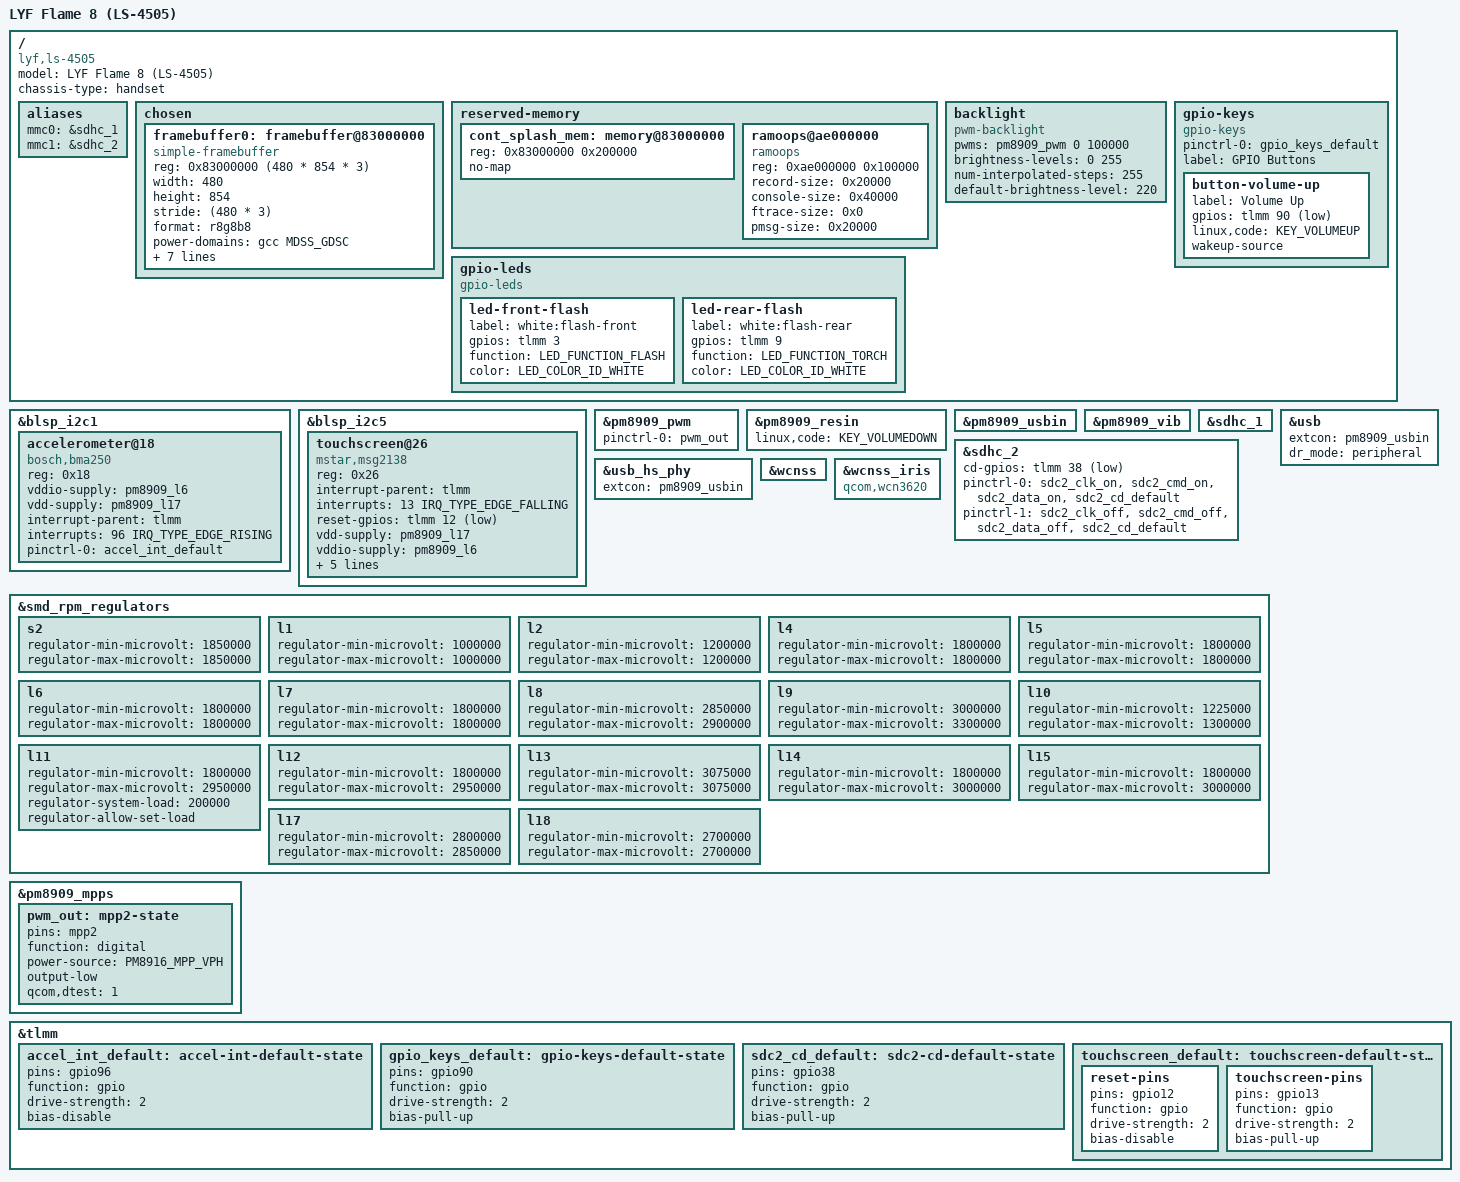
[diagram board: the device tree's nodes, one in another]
// SPDX-License-Identifier: GPL-2.0-only

/dts-v1/;

#include "qcom-msm8909-pm8909.dtsi"

#include <dt-bindings/gpio/gpio.h>
#include <dt-bindings/input/input.h>
#include <dt-bindings/interrupt-controller/irq.h>
#include <dt-bindings/leds/common.h>
#include <dt-bindings/pinctrl/qcom,pmic-mpp.h>

/ {
	model = "LYF Flame 8 (LS-4505)";
	compatible = "lyf,ls-4505", "qcom,msm8909";
	chassis-type = "handset";

	aliases {
		mmc0 = &sdhc_1;
		mmc1 = &sdhc_2;
	};

	chosen {
		#address-cells = <1>;
		#size-cells = <1>;
		ranges;

		framebuffer0: framebuffer@83000000 {
			compatible = "simple-framebuffer";
			reg = <0x83000000 (480 * 854 * 3)>;
			width = <480>;
			height = <854>;
			stride = <(480 * 3)>;
			format = "r8g8b8";

			power-domains = <&gcc MDSS_GDSC>;
			clocks = <&gcc GCC_MDSS_AHB_CLK>,
				 <&gcc GCC_MDSS_AXI_CLK>,
				 <&gcc GCC_MDSS_VSYNC_CLK>,
				 <&gcc GCC_MDSS_MDP_CLK>,
				 <&gcc GCC_MDSS_BYTE0_CLK>,
				 <&gcc GCC_MDSS_PCLK0_CLK>,
				 <&gcc GCC_MDSS_ESC0_CLK>;
		};
	};

	reserved-memory {
		#address-cells = <1>;
		#size-cells = <1>;
		ranges;

		cont_splash_mem: memory@83000000 {
			reg = <0x83000000 0x200000>;
			no-map;
		};

		ramoops@ae000000 {
			compatible = "ramoops";
			reg = <0xae000000 0x100000>;
			record-size = <0x20000>;
			console-size = <0x40000>;
			ftrace-size = <0x0>;
			pmsg-size = <0x20000>;
		};
	};

	backlight: backlight {
		compatible = "pwm-backlight";
		pwms = <&pm8909_pwm 0 100000>;
		brightness-levels = <0 255>;
		num-interpolated-steps = <255>;
		default-brightness-level = <220>;
	};

	gpio-keys {
		compatible = "gpio-keys";
		pinctrl-0 = <&gpio_keys_default>;
		pinctrl-names = "default";
		label = "GPIO Buttons";

		button-volume-up {
			label = "Volume Up";
			gpios = <&tlmm 90 GPIO_ACTIVE_LOW>;
			linux,code = <KEY_VOLUMEUP>;
			wakeup-source;
		};
	};

	gpio-leds {
		compatible = "gpio-leds";

		led-front-flash {
			label = "white:flash-front";
			gpios = <&tlmm 3 GPIO_ACTIVE_HIGH>;
			function = LED_FUNCTION_FLASH;
			color = <LED_COLOR_ID_WHITE>;
		};

		led-rear-flash {
			label = "white:flash-rear";
			gpios = <&tlmm 9 GPIO_ACTIVE_HIGH>;
			function = LED_FUNCTION_TORCH;
			color = <LED_COLOR_ID_WHITE>;
		};
	};
};

&blsp_i2c1 {
	status = "okay";

	accelerometer@18 {
		compatible = "bosch,bma250";
		reg = <0x18>;

		vddio-supply = <&pm8909_l6>;
		vdd-supply = <&pm8909_l17>;

		interrupt-parent = <&tlmm>;
		interrupts = <96 IRQ_TYPE_EDGE_RISING>;

		pinctrl-0 = <&accel_int_default>;
		pinctrl-names = "default";
	};
};

&blsp_i2c5 {
	status = "okay";

	touchscreen@26 {
		compatible = "mstar,msg2138";
		reg = <0x26>;

		interrupt-parent = <&tlmm>;
		interrupts = <13 IRQ_TYPE_EDGE_FALLING>;
		reset-gpios = <&tlmm 12 GPIO_ACTIVE_LOW>;

		vdd-supply = <&pm8909_l17>;
		vddio-supply = <&pm8909_l6>;

		touchscreen-size-x = <2048>;
		touchscreen-size-y = <2048>;

		linux,keycodes = <KEY_APPSELECT KEY_HOMEPAGE KEY_BACK>;

		pinctrl-0 = <&touchscreen_default>;
		pinctrl-names = "default";
	};
};

&pm8909_pwm {
	pinctrl-0 = <&pwm_out>;
	pinctrl-names = "default";
	status = "okay";
};

&pm8909_resin {
	linux,code = <KEY_VOLUMEDOWN>;
	status = "okay";
};

&pm8909_usbin {
	status = "okay";
};

&pm8909_vib {
	status = "okay";
};

&sdhc_1 {
	status = "okay";
};

&sdhc_2 {
	cd-gpios = <&tlmm 38 GPIO_ACTIVE_LOW>;
	pinctrl-0 = <&sdc2_clk_on &sdc2_cmd_on &sdc2_data_on &sdc2_cd_default>;
	pinctrl-1 = <&sdc2_clk_off &sdc2_cmd_off &sdc2_data_off &sdc2_cd_default>;
	pinctrl-names = "default", "sleep";
	status = "okay";
};

&usb {
	extcon = <&pm8909_usbin>;
	dr_mode = "peripheral";
	status = "okay";
};

&usb_hs_phy {
	extcon = <&pm8909_usbin>;
};

&wcnss {
	status = "okay";
};

&wcnss_iris {
	compatible = "qcom,wcn3620";
};

&smd_rpm_regulators {
	s2 {
		regulator-min-microvolt = <1850000>;
		regulator-max-microvolt = <1850000>;
	};
	l1 {
		regulator-min-microvolt = <1000000>;
		regulator-max-microvolt = <1000000>;
	};
	l2 {
		regulator-min-microvolt = <1200000>;
		regulator-max-microvolt = <1200000>;
	};
	l4 {
		regulator-min-microvolt = <1800000>;
		regulator-max-microvolt = <1800000>;
	};
	l5 {
		regulator-min-microvolt = <1800000>;
		regulator-max-microvolt = <1800000>;
	};
	l6 {
		regulator-min-microvolt = <1800000>;
		regulator-max-microvolt = <1800000>;
	};
	l7 {
		regulator-min-microvolt = <1800000>;
		regulator-max-microvolt = <1800000>;
	};
	l8 {
		regulator-min-microvolt = <2850000>;
		regulator-max-microvolt = <2900000>;
	};
	l9 {
		regulator-min-microvolt = <3000000>;
		regulator-max-microvolt = <3300000>;
	};
	l10 {
		regulator-min-microvolt = <1225000>;
		regulator-max-microvolt = <1300000>;
	};
	l11 {
		regulator-min-microvolt = <1800000>;
		regulator-max-microvolt = <2950000>;
		regulator-system-load = <200000>;
		regulator-allow-set-load;
	};
	l12 {
		regulator-min-microvolt = <1800000>;
		regulator-max-microvolt = <2950000>;
	};
	l13 {
		regulator-min-microvolt = <3075000>;
		regulator-max-microvolt = <3075000>;
	};
	l14 {
		regulator-min-microvolt = <1800000>;
		regulator-max-microvolt = <3000000>;
	};
	l15 {
		regulator-min-microvolt = <1800000>;
		regulator-max-microvolt = <3000000>;
	};
	l17 {
		regulator-min-microvolt = <2800000>;
		regulator-max-microvolt = <2850000>;
	};
	l18 {
		regulator-min-microvolt = <2700000>;
		regulator-max-microvolt = <2700000>;
	};
};

&pm8909_mpps {
	pwm_out: mpp2-state {
		pins = "mpp2";
		function = "digital";
		power-source = <PM8916_MPP_VPH>;
		output-low;
		qcom,dtest = <1>;
	};
};

&tlmm {
	accel_int_default: accel-int-default-state {
		pins = "gpio96";
		function = "gpio";
		drive-strength = <2>;
		bias-disable;
	};

	gpio_keys_default: gpio-keys-default-state {
		pins = "gpio90";
		function = "gpio";
		drive-strength = <2>;
		bias-pull-up;
	};

	sdc2_cd_default: sdc2-cd-default-state {
		pins = "gpio38";
		function = "gpio";
		drive-strength = <2>;
		bias-pull-up;
	};

	touchscreen_default: touchscreen-default-state {
		reset-pins {
			pins = "gpio12";
			function = "gpio";
			drive-strength = <2>;
			bias-disable;
		};

		touchscreen-pins {
			pins = "gpio13";
			function = "gpio";
			drive-strength = <2>;
			bias-pull-up;
		};
	};
};
